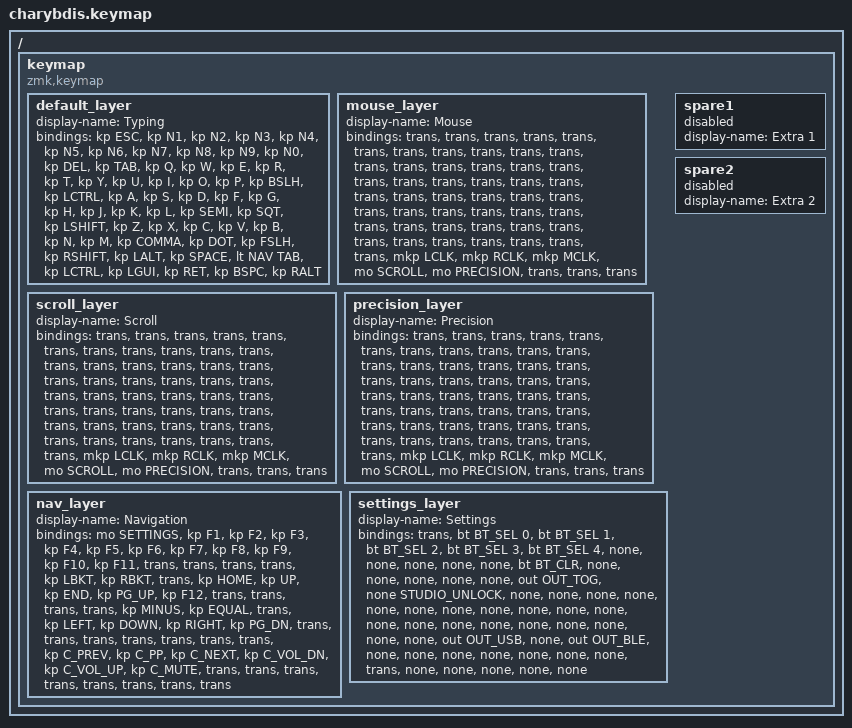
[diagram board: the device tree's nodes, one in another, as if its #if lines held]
#include <behaviors.dtsi>
#include <dt-bindings/zmk/keys.h>
#include <dt-bindings/zmk/bt.h>
#include <dt-bindings/zmk/outputs.h>
#include <dt-bindings/zmk/pointing.h>

#define BASE 0
#define MOUSE 1
#define SCROLL 2
#define PRECISION 3
#define NAV 4
#define SETTINGS 5

// Devicetree is processed before Kconfig; use the explicit Studio snippet flag.
#if defined(CHARYBDIS_STUDIO)
#define STUDIO_UNLOCK &studio_unlock
#else
#define STUDIO_UNLOCK &none
#endif

/ {
    keymap {
        compatible = "zmk,keymap";

        default_layer {
            display-name = "Typing";
            bindings = <
                &kp ESC  &kp N1  &kp N2  &kp N3  &kp N4  &kp N5  &kp N6  &kp N7  &kp N8  &kp N9  &kp N0  &kp DEL
                &kp TAB  &kp Q  &kp W  &kp E  &kp R  &kp T  &kp Y  &kp U  &kp I  &kp O  &kp P  &kp BSLH
                &kp LCTRL  &kp A  &kp S  &kp D  &kp F  &kp G  &kp H  &kp J  &kp K  &kp L  &kp SEMI  &kp SQT
                &kp LSHIFT  &kp Z  &kp X  &kp C  &kp V  &kp B  &kp N  &kp M  &kp COMMA  &kp DOT  &kp FSLH  &kp RSHIFT
                &kp LALT  &kp SPACE  &lt NAV TAB  &kp LCTRL  &kp LGUI
                &kp RET  &kp BSPC  &kp RALT
            >;
        };

        mouse_layer {
            display-name = "Mouse";
            bindings = <
                &trans  &trans  &trans  &trans  &trans  &trans  &trans  &trans  &trans  &trans  &trans  &trans
                &trans  &trans  &trans  &trans  &trans  &trans  &trans  &trans  &trans  &trans  &trans  &trans
                &trans  &trans  &trans  &trans  &trans  &trans  &trans  &trans  &trans  &trans  &trans  &trans
                &trans  &trans  &trans  &trans  &trans  &trans  &trans  &trans  &trans  &trans  &trans  &trans
                &mkp LCLK  &mkp RCLK  &mkp MCLK  &mo SCROLL  &mo PRECISION
                &trans  &trans  &trans
            >;
        };

        scroll_layer {
            display-name = "Scroll";
            bindings = <
                &trans  &trans  &trans  &trans  &trans  &trans  &trans  &trans  &trans  &trans  &trans  &trans
                &trans  &trans  &trans  &trans  &trans  &trans  &trans  &trans  &trans  &trans  &trans  &trans
                &trans  &trans  &trans  &trans  &trans  &trans  &trans  &trans  &trans  &trans  &trans  &trans
                &trans  &trans  &trans  &trans  &trans  &trans  &trans  &trans  &trans  &trans  &trans  &trans
                &mkp LCLK  &mkp RCLK  &mkp MCLK  &mo SCROLL  &mo PRECISION
                &trans  &trans  &trans
            >;
        };

        precision_layer {
            display-name = "Precision";
            bindings = <
                &trans  &trans  &trans  &trans  &trans  &trans  &trans  &trans  &trans  &trans  &trans  &trans
                &trans  &trans  &trans  &trans  &trans  &trans  &trans  &trans  &trans  &trans  &trans  &trans
                &trans  &trans  &trans  &trans  &trans  &trans  &trans  &trans  &trans  &trans  &trans  &trans
                &trans  &trans  &trans  &trans  &trans  &trans  &trans  &trans  &trans  &trans  &trans  &trans
                &mkp LCLK  &mkp RCLK  &mkp MCLK  &mo SCROLL  &mo PRECISION
                &trans  &trans  &trans
            >;
        };

        nav_layer {
            display-name = "Navigation";
            bindings = <
                &mo SETTINGS  &kp F1  &kp F2  &kp F3  &kp F4  &kp F5  &kp F6  &kp F7  &kp F8  &kp F9  &kp F10  &kp F11
                &trans  &trans  &trans  &trans  &kp LBKT  &kp RBKT  &trans  &kp HOME  &kp UP  &kp END  &kp PG_UP  &kp F12
                &trans  &trans  &trans  &trans  &kp MINUS  &kp EQUAL  &trans  &kp LEFT  &kp DOWN  &kp RIGHT  &kp PG_DN  &trans
                &trans  &trans  &trans  &trans  &trans  &trans  &kp C_PREV  &kp C_PP  &kp C_NEXT  &kp C_VOL_DN  &kp C_VOL_UP  &kp C_MUTE
                &trans  &trans  &trans  &trans  &trans
                &trans  &trans  &trans
            >;
        };

        settings_layer {
            display-name = "Settings";
            bindings = <
                &trans  &bt BT_SEL 0  &bt BT_SEL 1  &bt BT_SEL 2  &bt BT_SEL 3  &bt BT_SEL 4  &none  &none  &none  &none  &none  &bt BT_CLR
                &none  &none  &none  &none  &none  &out OUT_TOG  &none  STUDIO_UNLOCK  &none  &none  &none  &none
                &none  &none  &none  &none  &none  &none  &none  &none  &none  &none  &none  &none
                &none  &none  &none  &none  &out OUT_USB  &none  &out OUT_BLE  &none  &none  &none  &none  &none
                &none  &none  &trans  &none  &none
                &none  &none  &none
            >;
        };

        spare1 { status = "reserved"; display-name = "Extra 1"; };
        spare2 { status = "reserved"; display-name = "Extra 2"; };
    };
};
